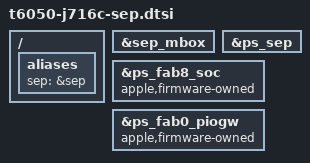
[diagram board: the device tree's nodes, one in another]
// SPDX-License-Identifier: GPL-2.0+ OR MIT
/* J716c SEP handoff and the providers needed for warm registration. */

/ {
	aliases {
		/* The loader supplies the reserved image and registration manifests. */
		sep = &sep;
	};
};

/* The SEP and its DART are enabled by the driver after its policy is selected. */
&sep_mbox {
	status = "okay";
};

&ps_sep {
	status = "okay";
};

/* Retain the fabric parents while the pre-booted enclave owns them. */
&ps_fab8_soc {
	apple,firmware-owned;
	status = "okay";
};

&ps_fab0_piogw {
	apple,firmware-owned;
	status = "okay";
};
